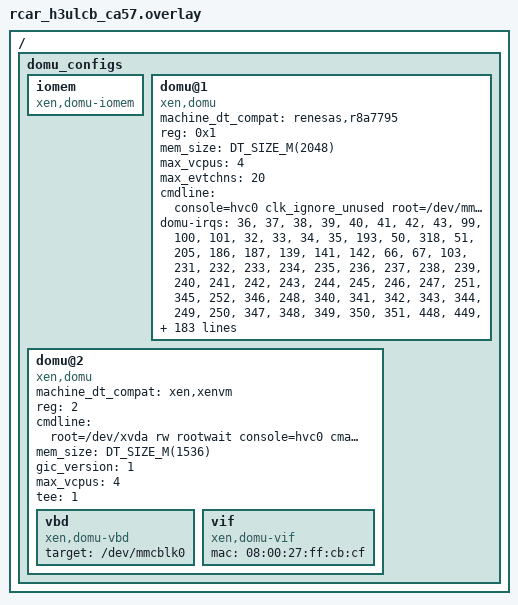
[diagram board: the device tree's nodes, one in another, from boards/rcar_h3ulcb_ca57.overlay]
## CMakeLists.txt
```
# SPDX-License-Identifier: Apache-2.0
# Copyright (c) 2024 EPAM Systems

cmake_minimum_required(VERSION 3.13.1)

find_package(Zephyr REQUIRED HINTS $ENV{ZEPHYR_BASE})

include($ENV{ZEPHYR_BASE}/cmake/app/boilerplate.cmake NO_POLICY_SCOPE)

project(xen-dom0)

include_directories(app PRIVATE ${CMAKE_CURRENT_SOURCE_DIR}/include)

# Add prebuilt to includes so assembler can find this files
include_directories(app PRIVATE ${CMAKE_CURRENT_SOURCE_DIR}/prebuilt)

target_sources(app PRIVATE src/dom0.c src/domain_bins.S)
target_sources_ifdef(CONFIG_DOM_STORAGE_FATFS_ENABLE app PRIVATE src/storage.c)
target_sources_ifdef(CONFIG_DOM_COVERAGE_ENABLE app PRIVATE src/cmd_gcov.c)

if(CONFIG_USE_DEFAULT_DOM_CFG)
  target_sources(app PRIVATE src/domu_cfg.c)
else()
  if(CONFIG_DOM_CFG_BOARD_EXT)
    target_sources(app PRIVATE src/dom_cfg/${BOARD}_${CONFIG_DOM_CFG_BOARD_EXT}.c)
  else()
    target_sources(app PRIVATE src/dom_cfg/${BOARD}.c)
  endif()
endif()

target_sources_ifdef(CONFIG_VCHAN_SHELL_CMDS app PRIVATE src/vchan_cmds.c)
```

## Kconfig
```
# Copyright (c) 2024 EPAM Systems
#
# SPDX-License-Identifier: Apache-2.0

config USE_DEFAULT_DOM_CFG
	bool "Use default guest domain cfg"
	default y
	help
	  Use default guest domain cfg from domu_cfg.c for build.
	  if not selected the guest domain cfg source file will be selected as basing
	  on board/platform:
	    dom_cfg/${BOARD}.c.
	  For example, for RPI 5 the dom_cfg/rpi_5.c will be used.

config DOM_CFG_BOARD_EXT
	string "Use extention string to determine guest domain cfg"
	depends on !USE_DEFAULT_DOM_CFG
	help
	  Use it to add extention string to determine guest domain cfg file to build.
	  The guest domain cfg source file will be selected as following:
	    dom_cfg/${BOARD}_${DOM_CFG_BOARD_EXT}.c
	  This allows to specify number of guest domain configs for the same board.
	  For example:
	    rpi_5_xenvm.c
	    rpi_5_domu.c

config DOM_STORAGE_FATFS_ENABLE
	bool "Enable FATFS disk storage for reading domains kernels/dtb images"
	default n
	select DISK_ACCESS
	select FILE_SYSTEM
	select FAT_FILESYSTEM_ELM
	select XRUN
	help
	  Enables FATFS disk storage and adds possibility to read guest domains
	  kernels/dtb images from storage.

if DOM_STORAGE_FATFS_ENABLE

config DOM_DISK_DRIVE_NAME
	string "Disk drive name for Domain-0"
	default "SD"
	help
	  Used by disk subsys to establish disk access and should be in
	  sync with "disk-name" device tree propery, formerly it was
	  CONFIG_SDMMC_VOLUME_NAME in Zephyr.

config FS_FATFS_MOUNT_MKFS
	default n

config FS_FATFS_WINDOW_ALIGNMENT
	default SDHC_BUFFER_ALIGNMENT

config FS_FATFS_LBA64
	default y

config FS_FATFS_EXFAT
	default y

config DOM_STORAGE_FATFS_DIR
	string "FATFS folder where domains kernels/dtb images"
	default "dom0/"
	help
	  FATFS folder where domains kernels/dtb images are located.
	  It should be ended with "/" symbol.

config DOM_STORAGE_FATFS_LOGICAL_DRIVE_NAME
	string "FATFS logical drive name to be used as mount point"
	default "0" if FS_MULTI_PARTITION
	default DOM_DISK_DRIVE_NAME
	help
	  FATFS logical drive name to be used as mount point.

config DOM_CFG_LINUX_PV_DOMAIN
	bool "Enable PV domain support loaded from FATFS storage"
	help
	  Adds Linux-based domain with enabled pvnet and pvblock devices.
	  It is expected to be placed on the storage device, connected to
	  Dom0.

endif #DOM_STORAGE_FATFS_ENABLE

config DOM_CFG_BUILTIN_IMAGES
	bool "Use built-in guest domains kernel/device-tree images"
	default y
	help
	  Use built-in guest domains kernel/device-tree images.

if DOM_CFG_BUILTIN_IMAGES

config DOM_CFG_DOMU0_IMAGE_BIN_FILE
	string "Location for Domain-U0 kernel binary"
	default "domu0_img.bin"

config DOM_CFG_DOMU0_DTB_BIN_FILE
	string "Location for Domain-U0 device-tree"
	default "domu0.dtb"

config DOM_CFG_DOMU1_ENABLE
	bool "Enable builtin Domain-U1 kernel binary"
	default n

config DOM_CFG_DOMU1_IMAGE_BIN_FILE
	string "Location for Domain-U1 kernel binary"
	depends on DOM_CFG_DOMU1_ENABLE

config DOM_CFG_DOMU1_DTB_BIN_FILE
	string "Location for Domain-U1 device-tree"
	depends on DOM_CFG_DOMU1_ENABLE

endif #DOM_CFG_BUILTIN_IMAGES

config DOM_COVERAGE_ENABLE
	bool "Enable code coverage with GCOV"
	depends on SHELL
	select FORCE_COVERAGE
	select COVERAGE
	help
	  Enable code coverage with GCOV and enable shell command to print GCOV
	  dump "gcov dump" in console.

config VCHAN_SHELL_CMDS
	depends on SHELL
	bool "Enable VCHAN echo server shell commands"
	help
	  Enable set of VCHAN echo server shell commands. All data incoming to
	  channel created by this server will be send back. This is for test
	  purposes. Server introduces 2 commands:
	  vchan start [domid]
	    Start echo server. domid - The peer domain that will be connecting
	    (0 by default)
	  vchan stop
	    Stop server

if VCHAN_SHELL_CMDS

config VCHAN_ECHO_BUFFER_SIZE
	int "Buffer size for echo server"
	default 10

config VCHAN_THREAD_STACK_SIZE
	int "vchan echo server thread size"
	default 2048

endif #VCHAN_SHELL_CMDS

source "Kconfig.zephyr"
```

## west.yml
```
# SPDX-License-Identifier: Apache-2.0
# West YAML manifest for Zephyr as Xen Dom0

manifest:
  self:
    path: zephyr-dom0-xt

  remotes:
    - name: xentroops
      url-base: https://github.com/xen-troops/
    - name: zephyrproject-rtos
      url-base: https://github.com/zephyrproject-rtos/

  projects:
    - name: zephyr
      remote: xentroops
      revision: zephyr-v4.4.0-xt
      west-commands: scripts/west-commands.yml
    - name: zephyr-xenlib
      remote: xentroops
      revision: main
    - name: fatfs
      remote: zephyrproject-rtos
      revision: f4ead3bf4a6dab3a07d7b5f5315795c073db568d
    - name: zephyr-xrun
      remote: xentroops
      revision: main
```

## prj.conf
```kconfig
CONFIG_MP_MAX_NUM_CPUS=1
CONFIG_XEN_STORE_SRV=y
CONFIG_XEN_DOMAIN_MANAGEMENT=y
CONFIG_XEN_SHELL=y
CONFIG_XEN_CONSOLE_SRV=y
CONFIG_HEAP_MEM_POOL_SIZE=2097152
CONFIG_SHELL_STACK_SIZE=4096
CONFIG_XEN_REGIONS=y

CONFIG_LOG=y
CONFIG_LOG_MODE_MINIMAL=y
```

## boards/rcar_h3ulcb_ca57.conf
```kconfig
# Copyright (c) 2024 EPAM Systems
# SPDX-License-Identifier: Apache-2.0

CONFIG_KERNEL_VM_SIZE=0x10000000
CONFIG_CLOCK_CONTROL=n
CONFIG_PINCTRL=n
```

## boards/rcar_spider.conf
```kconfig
# Copyright (c) 2024 EPAM Systems
# SPDX-License-Identifier: Apache-2.0

CONFIG_KERNEL_VM_SIZE=0x10000000
```

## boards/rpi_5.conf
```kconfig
# Copyright (c) 2024 EPAM Systems
# SPDX-License-Identifier: Apache-2.0

CONFIG_XEN_DOM0=y

CONFIG_XSTAT=y
CONFIG_XSTAT_SHELL_CMDS=y

CONFIG_SHELL_STACK_SIZE=4096

CONFIG_MAIN_STACK_SIZE=8192
CONFIG_ISR_STACK_SIZE=8192

CONFIG_XEN_VCH=y
CONFIG_XEN_DOM0LESS_BOOT=y

CONFIG_USE_DEFAULT_DOM_CFG=n
CONFIG_DOM_CFG_BUILTIN_IMAGES=n

CONFIG_DOM_STORAGE_FATFS_ENABLE=y

CONFIG_FILE_SYSTEM_SHELL=y

CONFIG_NOCACHE_MEMORY=y
CONFIG_FS_FATFS_MULTI_PARTITION=y
CONFIG_FS_FATFS_CUSTOM_MOUNT_POINT_COUNT=8
CONFIG_FS_FATFS_CUSTOM_MOUNT_POINTS="RAM,NAND,CF,SD,SD2,USB,USB2,USB3"
CONFIG_DOM_STORAGE_FATFS_LOGICAL_DRIVE_NAME="1"
CONFIG_DOM_STORAGE_FATFS_DIR="dom0/"
CONFIG_XEN_LIBFDT=y

CONFIG_DOM_CFG_LINUX_PV_DOMAIN=y

CONFIG_XRUN_STORAGE_DMA_DEBOUNCE=4

CONFIG_DOMU_MAX=5

CONFIG_XEN_SYSCTL_INTERFACE_VERSION=0x16
CONFIG_XEN_DOMCTL_INTERFACE_VERSION=0x18
CONFIG_XEN_DOMCTL_XENTROOPS_ARCH_VGSX_OSID=y
CONFIG_XEN_DOMCTL_XENTROOPS_ARCH_SCI_TYPE=y

CONFIG_PCIE=n
CONFIG_PCIE_CONTROLLER=n
```

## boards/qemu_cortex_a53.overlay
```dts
/*
 * Copyright (C) 2023 Renesas Electronics Corporation.
 * Copyright (C) 2023 EPAM Systems, Inc.
 *
 * SPDX-License-Identifier: Apache-2.0
 */

#include <mem.h>

/delete-node/ &sram0;

&uart0 {
	/* Xen consoleio will be used */
	status = "disabled";
};

/ {
	/*
	 * This node may differs on different setups, please check
	 * following line in Xen boot log to set it right:
	 * (XEN) Grant table range: 0x00000040200000-0x00000040240000
	 * Also, add extended region 1:
	 * (XEN) Extended region 1: 0x40000000->0x47e00000
	 *
	 * Xen passes actual values for setup in domain device tree, but Zephyr
	 * is not capable to parse and handle it in runtime.
	 */
	hypervisor: hypervisor@40200000 {
		compatible = "xen,xen";
		reg = <0x0 0x40200000 0x0 0x40000 0x0 0x40400000 0x0 0x17C00000>;
		interrupts = <GIC_PPI 0x0 IRQ_TYPE_EDGE IRQ_DEFAULT_PRIORITY>;
		interrupt-parent = <&gic>;
		status = "okay";
	};

	/*
	 * This node may differs on different setups, because Xen picks
	 * region for Domain-0 for every specific configuration. You can
	 * start Xen for your platform and check following log:
	 * (XEN) Allocating 1:1 mappings for dom0:
	 * (XEN) BANK[0] 0x00000058000000-0x00000060000000 (128MB)
	 *
	 * Xen passes actual values for setup in domain device tree, but Zephyr
	 * is not capable to parse and handle it in runtime.
	 */
	soc {
		sram0: memory@58000000 {
			device_type = "mmio-sram";
			reg = <0x00 0x58000000 0x00 DT_SIZE_M(128)>;
		};
	};
};
```

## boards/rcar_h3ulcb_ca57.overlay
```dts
/*
 * Copyright (C) 2024 EPAM Systems, Inc.
 * SPDX-License-Identifier: Apache-2.0
 */
#include <mem.h>

/delete-node/ &sd0;
/delete-node/ &vcc_sd0;
/delete-node/ &vccq_sd0;
/delete-node/ &gpio5;

/ {
	domu_configs {
		#address-cells = <1>;
		#size-cells = <0>;

		/* it is needed only for correct filling structures by macros */
		iomem: iomem {
			compatible = "xen,domu-iomem";
			#iomem-cells = <3>;
		};

		domu@1 {
			/*
			 * Most of the properties of this one and children nodes are default and don't appear
			 * in the resulting dts.
			 *
			 * Refer to 'xen,domu.yaml', 'xen,domu-vbd.yaml' and 'xen,domu-vif.yaml' for details.
			 */
			compatible = "xen,domu";
			machine_dt_compat = "renesas,r8a7795";

			reg = <0x1>;
			mem_size = <DT_SIZE_M(2048)>;
			max_vcpus = <4>;
			max_evtchns = <20>;

			cmdline = "console=hvc0 clk_ignore_unused root=/dev/mmcblk1 rw rootwait pvrsrvkm.DriverMode=0";

			domu-irqs =
				// gpio@e6050000
				<36>,
				// gpio@e6051000
				<37>,
				// gpio@e6052000
				<38>,
				// gpio@e6053000
				<39>,
				// gpio@e6054000
				<40>,
				// gpio@e6055000
				<41>,
				// gpio@e6055400
				<42>,
				// gpio@e6055800
				<43>,
				// thermal@e6198000
				<99>, <100>, <101>,
				// interrupt-controller@e61c0000
				<32>, <33>, <34>, <35>, <193>, <50>,
				// i2c@e6510000
				<318>,
				// i2c@e66d8000
				<51>,
				// i2c@e60b0000
				<205>,
				// serial@e6540000
				<186>,
				// serial@e6550000
				<187>,
				// usb@e6590000
				<139>,
				// dma-controller@e65a0000
				<141>,
				// dma-controller@e65b0000
				<142>,
				// dma-controller@e6460000
				<66>,
				// dma-controller@e6470000
				<67>,
				// crypto@e6601000
				<103>,
				// dma-controller@e6700000
				<231>, <232>, <233>, <234>, <235>, <236>, <237>, <238>, <239>, <240>, <241>, <242>, <243>, <244>, <245>, <246>, <247>,
				// dma-controller@e7300000
				<251>, <345>, <252>, <346>, <248>, <340>, <341>, <342>, <343>, <344>, <249>, <250>, <347>, <348>, <349>, <350>, <351>,
				// dma-controller@e7310000
				<448>, <449>, <450>, <451>, <452>, <453>, <454>, <455>, <456>, <457>, <458>, <459>, <460>, <461>, <462>, <463>, <429>,
				// ethernet@e6800000
				<71>, <72>, <73>, <74>, <75>, <76>, <77>, <78>, <79>, <80>, <81>, <82>, <83>, <84>, <85>, <86>, <87>, <88>, <89>, <90>, <91>, <92>, <93>, <94>, <95>,
				// can@e6c30000
				<218>,
				// can@e6c38000
				<219>,
				// serial@e6e68000
				<185>,
				// video@e6ef0000
				<220>,
				// video@e6ef1000
				<221>,
				// video@e6ef2000
				<222>,
				// video@e6ef3000
				<223>,
				// video@e6ef4000
				<206>,
				// video@e6ef5000
				<207>,
				// src-0
				<384>,
				// src-1
				<385>,
				// src-2
				<386>,
				// src-3
				<387>,
				// src-4
				<388>,
				// src-5
				<389>,
				// src-6
				<390>,
				// src-7
				<391>,
				// src-8
				<392>,
				// src-9
				<393>,
				// ssi-0
				<402>,
				// ssi-1
				<403>,
				// ssi-2
				<404>,
				// ssi-3
				<405>,
				// ssi-4
				<406>,
				// ssi-5
				<407>,
				// ssi-6
				<408>,
				// ssi-7
				<409>,
				// ssi-8
				<410>,
				// ssi-9
				<411>,
				// dma-controller@ec700000
				<352>, <353>, <354>, <355>, <356>, <357>, <358>, <359>, <360>, <361>, <362>, <363>, <364>, <365>, <366>, <367>, <382>,
				// dma-controller@ec720000
				<383>, <368>, <369>, <370>, <371>, <372>, <373>, <374>, <375>, <376>, <377>, <378>, <379>, <380>, <381>, <414>, <415>,
				// usb@ee000000
				<134>,
				// usb@ee080000
				<140>,
				// usb@ee0a0000
				<144>,
				// mmc@ee100000
				<197>,
				// mmc@ee140000
				<199>,
				// mmc@ee160000
				<200>,
				// gsx@fd000000
				<151>,
				// pcie@fe000000
				<148>, <149>, <150>,
				// pcie@ee800000
				<180>, <181>, <182>,
				// imr-lx4@fe860000
				<224>,
				// imr-lx4@fe870000
				<225>,
				// imr-lx4@fe880000
				<226>,
				// imr-lx4@fe890000
				<227>,
				// vcp4@fe8d0000
				<412>, <413>, <255>,
				// vcp4@fe910000
				<292>, <293>,
				// vcp4@fe900000
				<272>, <273>,
				// fdpm@fe940000
				<294>,
				// fdpm@fe944000
				<295>,
				// vspm@fe960000
				<298>,
				// vspm@fe920000
				<497>,
				// vsp@fea20000
				<498>,
				// vsp@fea28000
				<499>,
				// vsp@fea30000
				<500>,
				// vspm@fe9a0000
				<476>,
				// vspm@fe9b0000
				<477>,
				// csi2@fea80000
				<216>,
				// csi2@feaa0000
				<278>,
				// hdmi@fead0000
				<421>,
				// display@feb00000
				<288>, <300>, <301>, <302>,
				// impdes0
				<471>,
				// imprtt
				<425>,
				// dma-controller@ffc10000
				<480>, <481>, <482>, <483>, <484>, <485>, <486>, <487>, <488>,
				// dma-controller@ffc20000
				<501>, <489>, <490>, <491>, <492>, <493>, <494>, <495>, <496>;

			dt-passthrough =
				"/audio_clk_a",
				"/audio_clk_b",
				"/audio_clk_c",
				"/can",
				"/extal",
				"/extalr",
				"/gsx_opp_table0",
				"/gsx_opp_table1",
				"/gsx_opp_table2",
				"/gsx_opp_table3",
				"/gsx_opp_table4",
				"/gsx_opp_table5",
				"/gsx_opp_table6",
				"/gsx_opp_table7",
				"/pcie_bus",
				"/scif",
				"/soc",
				"/usb3s0",
				"/usb_extal",
				"/audio-clkout",
				"/avb-mch",
				"/hdmi0-out",
				"/keyboard",
				"/leds",
				"/regulator0",
				"/regulator1",
				"/regulator-vcc-sdhi0",
				"/regulator-vccq-sdhi0",
				"/x12",
				"/x23-clock",
				"/vspm_if",
				"/versaclk-3",
				"/versaclk-4",
				"/clksndsel",
				"/regulator-snd_3p3v",
				"/regulator-snd_vcc5v",
				"/regulator-wlan_en",
				"/regulator@9",
				"/regulator@11",
				"/regulator@12",
				"/regulator@13",
				"/regulator@14",
				"/regulator@15",
				"/regulator@16",
				"/regulator@17",
				"/kim",
				"/sound@0",
				"/sound@1",
				"/sound@2",
				"/sound@3",
				"/lvds",
				"/hdmi-out",
				"/si468x@0",
				"/wl18xx_pcm@0",
				"/camera_clk",
				"/ov5647_camera_clk",
				"/reserved-memory",
				"/mmngr",
				"/mmngrbuf",
				"/__symbols__";

			dtdevs =
				"/soc/dma-controller@e65a0000",
				"/soc/dma-controller@e65b0000",
				"/soc/dma-controller@e6460000",
				"/soc/dma-controller@e6470000",
				"/soc/dma-controller@e6700000",
				"/soc/dma-controller@e7300000",
				"/soc/dma-controller@e7310000",
				"/soc/ethernet@e6800000",
				"/soc/video@e6ef0000",
				"/soc/video@e6ef1000",
				"/soc/video@e6ef2000",
				"/soc/video@e6ef3000",
				"/soc/video@e6ef4000",
				"/soc/video@e6ef5000",
				"/soc/dma-controller@ec700000",
				"/soc/dma-controller@ec720000",
				"/soc/usb@ee000000",
				"/soc/usb@ee080000",
				"/soc/usb@ee0a0000",
				"/soc/usb@ee080100",
				"/soc/usb@ee0a0100",
				"/soc/mmc@ee100000",
				"/soc/mmc@ee140000",
				"/soc/mmc@ee160000",
				"/soc/pcie@fe000000",
				"/soc/pcie@ee800000",
				"/soc/imr-lx4@fe860000",
				"/soc/imr-lx4@fe870000",
				"/soc/imr-lx4@fe880000",
				"/soc/imr-lx4@fe890000",
				"/soc/fdpm@fe940000",
				"/soc/fdpm@fe944000",
				"/soc/fcp@fea27000",
				"/soc/fcp@fea2f000",
				"/soc/fcp@fea37000",
				"/soc/vspm@fe960000",
				"/soc/vspm@fe920000",
				"/soc/vspm@fe9a0000",
				"/soc/vspm@fe9b0000",
				"/soc/hdmi@fead0000",
				"/soc/impdm0",
				"/soc/gsx_pv0_domd",
				"/soc/gsx_pv1_domd",
				"/soc/gsx_pv2_domd",
				"/soc/gsx_pv3_domd",
				"/soc/fcpcs_vc0",
				"/soc/fcpcs_vc1",
				"/soc/dma-controller@ffc10000",
				"/soc/dma-controller@ffc20000";

			iomems =
				<&iomem 0x47fd7 0x1 0xe0000>,
				// 1:1 mapped lossy_decompress region
				<&iomem 0x54000 0x3000 0x0>,
				// mfis@e6260000
				<&iomem 0xe6260 0x1 0x0>,
				// watchdog@e6020000
				<&iomem 0xe6020 0x1 0x0>,
				// gpio@e6050000
				<&iomem 0xe6050 0x1 0x0>,
				// gpio@e6051000
				<&iomem 0xe6051 0x1 0x0>,
				// gpio@e6052000
				<&iomem 0xe6052 0x1 0x0>,
				// gpio@e6053000
				<&iomem 0xe6053 0x1 0x0>,
				// gpio@e6054000
				<&iomem 0xe6054 0x1 0x0>,
				// gpio@e6055000
				// gpio@e6055400
				// gpio@e6055800
				<&iomem 0xe6055 0x1 0x0>,
				// pinctrl@e6060000
				<&iomem 0xe6060 0x1 0x0>,
				// avs@e60a013c
				<&iomem 0xe60a0 0x1 0x0>,
				// clock-controller@e6150000
				// imprtt
				<&iomem 0xe6150 0x1 0x0>,
				// reset-controller@e6160000
				<&iomem 0xe6160 0x1 0x0>,
				// system-controller@e6180000
				<&iomem 0xe6180 0x1 0x0>,
				// thermal@e6198000
				<&iomem 0xe6198 0x1 0x0>,
				// thermal@e6198000
				<&iomem 0xe61a0 0x1 0x0>,
				// thermal@e6198000
				<&iomem 0xe61a8 0x1 0x0>,
				// interrupt-controller@e61c0000
				<&iomem 0xe61c0 0x1 0x0>,
				// i2c@e6510000
				<&iomem 0xe6510 0x1 0x0>,
				// i2c@e66d8000
				<&iomem 0xe66d8 0x1 0x0>,
				// i2c@e60b0000
				<&iomem 0xe60b0 0x1 0x0>,
				// serial@e6540000
				<&iomem 0xe6540 0x1 0x0>,
				// serial@e6550000
				<&iomem 0xe6550 0x1 0x0>,
				// usb@e6590000
				<&iomem 0xe6590 0x1 0x0>,
				// dma-controller@e65a0000
				<&iomem 0xe65a0 0x1 0x0>,
				// dma-controller@e65b0000
				<&iomem 0xe65b0 0x1 0x0>,
				// dma-controller@e6460000
				<&iomem 0xe6460 0x1 0x0>,
				// dma-controller@e6470000
				<&iomem 0xe6470 0x1 0x0>,
				// crypto@e6601000
				<&iomem 0xe6601 0x1 0x0>,
				// dma-controller@e6700000
				<&iomem 0xe6700 0x10 0x0>,
				// dma-controller@e7300000
				<&iomem 0xe7300 0x10 0x0>,
				// dma-controller@e7310000
				<&iomem 0xe7310 0x10 0x0>,
				// qos@e67e0000
				<&iomem 0xe67e0 0x11 0x0>,
				// ethernet@e6800000
				<&iomem 0xe6800 0x1 0x0>,
				// ethernet@e6800000
				<&iomem 0xe6a00 0x10 0x0>,
				// can@e6c30000
				<&iomem 0xe6c30 0x1 0x0>,
				// can@e6c38000
				<&iomem 0xe6c38 0x1 0x0>,
				// serial@e6e68000
				<&iomem 0xe6e68 0x1 0x0>,
				// video@e6ef0000
				<&iomem 0xe6ef0 0x1 0x0>,
				// video@e6ef1000
				<&iomem 0xe6ef1 0x1 0x0>,
				// video@e6ef2000
				<&iomem 0xe6ef2 0x1 0x0>,
				// video@e6ef3000
				<&iomem 0xe6ef3 0x1 0x0>,
				// video@e6ef4000
				<&iomem 0xe6ef4 0x1 0x0>,
				// video@e6ef5000
				<&iomem 0xe6ef5 0x1 0x0>,
				// sound@ec500000
				<&iomem 0xec500 0x1 0x0>,
				// sound@ec500000
				// avb-mch
				<&iomem 0xec5a0 0x1 0x0>,
				// sound@ec500000
				<&iomem 0xec540 0x1 0x0>,
				// sound@ec500000
				<&iomem 0xec541 0x1 0x0>,
				// sound@ec500000
				<&iomem 0xec760 0x1 0x0>,
				// sound@ec500000
				<&iomem 0xec000 0x1 0x0>,
				// sound@ec500000
				<&iomem 0xec008 0x1 0x0>,
				// sound@ec500000
				<&iomem 0xec100 0x100 0x0>,
				// dma-controller@ec700000
				<&iomem 0xec700 0x10 0x0>,
				// dma-controller@ec720000
				<&iomem 0xec720 0x10 0x0>,
				// usb@ee000000
				<&iomem 0xee000 0x1 0x0>,
				// usb@ee080000
				// usb@ee080100
				// usb-phy@ee080200
				<&iomem 0xee080 0x1 0x0>,
				// usb@ee0a0000
				// usb@ee0a0100
				// usb-phy@ee0a0200
				<&iomem 0xee0a0 0x1 0x0>,
				// mmc@ee100000
				<&iomem 0xee100 0x2 0x0>,
				// mmc@ee140000
				<&iomem 0xee140 0x2 0x0>,
				// mmc@ee160000
				<&iomem 0xee160 0x2 0x0>,
				// gsx@fd000000
				<&iomem 0xfd000 0x40 0x0>,
				// pcie@fe000000
				<&iomem 0xfe000 0x80 0x0>,
				// pcie@ee800000
				<&iomem 0xee800 0x80 0x0>,
				// imr-lx4@fe860000
				// imrlx4_imr0
				<&iomem 0xfe860 0x2 0x0>,
				// imr-lx4@fe870000
				// imrlx4_imr1
				<&iomem 0xfe870 0x2 0x0>,
				// imr-lx4@fe880000
				// imrlx4_imr2
				<&iomem 0xfe880 0x2 0x0>,
				// imr-lx4@fe890000
				// imrlx4_imr3
				<&iomem 0xfe890 0x2 0x0>,
				// vcp4@fe90f000
				<&iomem 0xfe90f 0x1 0x0>,
				// vcp4@fe8d0000
				// vcp4@fe8d0000
				<&iomem 0xfe8d0 0x1 0x0>,
				// vcp4@fe910000
				// vcp4@fe910000
				<&iomem 0xfe910 0x1 0x0>,
				// vcp4@fe900000
				// vcp4@fe900000
				<&iomem 0xfe900 0x1 0x0>,
				// fdpm@fe940000
				<&iomem 0xfe940 0x3 0x0>,
				// fdpm@fe940000
				<&iomem 0xfe950 0x1 0x0>,
				// fdpm@fe944000
				<&iomem 0xfe944 0x3 0x0>,
				// fdpm@fe944000
				<&iomem 0xfe951 0x1 0x0>,
				// fcp@fea27000
				<&iomem 0xfea27 0x1 0x0>,
				// fcp@fea2f000
				<&iomem 0xfea2f 0x1 0x0>,
				// fcp@fea37000
				<&iomem 0xfea37 0x1 0x0>,
				// vsp@fe960000
				// vspm@fe960000
				<&iomem 0xfe960 0x8 0x0>,
				// vspm@fe960000
				<&iomem 0xfe96f 0x1 0x0>,
				// vsp@fe920000
				// vspm@fe920000
				<&iomem 0xfe920 0x8 0x0>,
				// vspm@fe920000
				<&iomem 0xfe92f 0x1 0x0>,
				// vsp@fea20000
				<&iomem 0xfea20 0x5 0x0>,
				// vsp@fea28000
				<&iomem 0xfea28 0x5 0x0>,
				// vsp@fea30000
				<&iomem 0xfea30 0x5 0x0>,
				// vsp@fe9a0000
				// vspm@fe9a0000
				<&iomem 0xfe9a0 0x8 0x0>,
				// vspm@fe9a0000
				<&iomem 0xfe9af 0x1 0x0>,
				// vsp@fe9b0000
				// vspm@fe9b0000
				<&iomem 0xfe9b0 0x8 0x0>,
				// vspm@fe9b0000
				<&iomem 0xfe9bf 0x1 0x0>,
				// csi2@fea80000
				<&iomem 0xfea80 0x10 0x0>,
				// csi2@feaa0000
				<&iomem 0xfeaa0 0x10 0x0>,
				// hdmi@fead0000
				<&iomem 0xfead0 0x10 0x0>,
				// display@feb00000
				<&iomem 0xfeb00 0x80 0x0>,
				// lvds@feb90000
				<&iomem 0xfeb90 0x1 0x0>,
				// chipid@fff00044
				<&iomem 0xfff00 0x1 0x0>,
				// impdes0
				<&iomem 0xffa00 0x4 0x0>,
				// imp0
				<&iomem 0xff900 0x20 0x0>,
				// imp1
				<&iomem 0xff920 0x20 0x0>,
				// imp2
				<&iomem 0xff940 0x20 0x0>,
				// imp3
				<&iomem 0xff960 0x20 0x0>,
				// impsc0
				<&iomem 0xff980 0x10 0x0>,
				// impsc1
				<&iomem 0xff990 0x10 0x0>,
				// impsl0
				<&iomem 0xff9c0 0x10 0x0>,
				// impdm0
				<&iomem 0xffa10 0x4 0x0>,
				// impc0
				<&iomem 0xffa40 0x20 0x0>,
				// imprtt
				<&iomem 0xff8d0 0x1 0x0>,
				// dma-controller@ffc10000
				<&iomem 0xffc10 0x10 0x0>,
				// dma-controller@ffc20000
				<&iomem 0xffc20 0x10 0x0>,
				// cmm@fea40000
				<&iomem 0xfea40 0x1 0x0>,
				// cmm@fea50000
				<&iomem 0xfea50 0x1 0x0>,
				// cmm@fea60000
				<&iomem 0xfea60 0x1 0x0>,
				// cmm@fea70000
				<&iomem 0xfea70 0x1 0x0>;
		};

		domu@2 {
			compatible = "xen,domu";
			machine_dt_compat = "xen,xenvm";
			reg = <2>;

			cmdline = "root=/dev/xvda rw rootwait console=hvc0 cma=256M pvrsrvkm.DriverMode=1";

			mem_size = <DT_SIZE_M(1536)>;
			gic_version = <1>;
			max_vcpus = <4>;
			tee = <1>;

			vbd {
				compatible = "xen,domu-vbd";
				target = "/dev/mmcblk0";
			};

			vif {
				compatible = "xen,domu-vif";
				mac = "08:00:27:ff:cb:cf";
			};

			status = "okay";
		};
	};
};
```

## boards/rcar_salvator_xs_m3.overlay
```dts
/*
 * Copyright (C) 2023 Renesas Electronics Corporation.
 * Copyright (C) 2023 EPAM Systems, Inc.
 *
 * SPDX-License-Identifier: Apache-2.0
 */

#include <mem.h>

/delete-node/ &ram;

/ {
	/*
	 * This node may differs on different setups, please check
	 * following line in Xen boot log to set it right:
	 * (XEN) Grant table range: 0x00000088080000-0x000000880c0000
	 * Also, add extended region 2:
	 * (XEN) [    0.928173] d0: extended region 2: 0x40000000->0x47e00000
	 *
	 * Xen passes actual values for setup in domain device tree, but Zephyr
	 * is not capable to parse and handle it in runtime.
	 */
	hypervisor: hypervisor@88080000 {
		compatible = "xen,xen";
		reg = <0x0 0x88080000 0x0 0x40000 0x0 0x40000000 0x0 0x7e00000>;
		interrupts = <GIC_PPI 0x0 IRQ_TYPE_EDGE IRQ_DEFAULT_PRIORITY>;
		interrupt-parent = <&gic>;
		status = "okay";
	};

	/*
	 * This node may differs on different setups, because Xen picks
	 * region for Domain-0 for every specific configuration. You can
	 * start Xen for your platform and check following log:
	 * (XEN) Allocating 1:1 mappings for dom0:
	 * (XEN) BANK[0] 0x00000060000000-0x00000070000000 (256MB)
	 *
	 * Xen passes actual values for setup in domain device tree, but Zephyr
	 * is not capable to parse and handle it in runtime.
	 */
	ram: memory@60000000 {
		device_type = "mmio-sram";
		reg = <0x00 0x60000000 0x00 DT_SIZE_M(256)>;
	};
};
```

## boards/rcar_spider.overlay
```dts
/*
 * Copyright (C) 2024 EPAM Systems, Inc.
 * SPDX-License-Identifier: Apache-2.0
 */
#include <mem.h>

/ {
	domu_configs {
		#address-cells = <1>;
		#size-cells = <0>;

		/* it is needed only for correct filling structures by macros */
		iomem: iomem {
			compatible = "xen,domu-iomem";
			#iomem-cells = <3>;
		};

		domu@1 {
			/*
			 * Most of the properties of this one and children nodes are default and don't appear
			 * in the resulting dts.
			 *
			 * Refer to 'xen,domu.yaml', 'xen,domu-vbd.yaml' and 'xen,domu-vif.yaml' for details.
			 */
			compatible = "xen,domu";
			machine_dt_compat = "renesas,r8a779f0";

			reg = <0x1>;
			mem_size = <DT_SIZE_M(1024)>;
			cmdline = "console=hvc0 clk_ignore_unused root=/dev/nfs rw rootwait nfsroot=192.168.1.100:/srv/domd,vers=3 ip=dhcp pci=pcie_bus_perf";

			gic_version = <2>;
			max_vcpus = <4>;
			tee = <1>;

			domu-irqs =
				// gpio@e6050180
				<854>,
				// gpio@e6050980
				<858>,
				// gpio@e6051180
				<948>,
				// gpio@e6051980
				<952>,
				// i2c@e6500000
				<270>,
				// i2c@e66d8000
				<274>,
				// serial@e6550000
				<278>,
				// serial@e6e60000
				<281>,
				// serial@e6c50000 - used by Xen
				//    <284>,
				// dma-controller@e7350000
				<133>, <134>, <135>, <136>, <137>, <138>, <139>, <140>, <141>, <142>, <143>, <144>, <145>, <146>, <147>, <148>, <149>,
				// dma-controller@e7351000
				<151>, <158>, <157>, <152>, <179>, <180>, <181>, <182>, <183>, <184>, <185>, <186>, <155>, <156>, <154>, <153>, <159>,
				// mmc@ee140000
				<268>,
				// dma-controller@ffd60000
				<64>, <65>, <66>, <67>, <68>, <69>, <70>, <71>, <72>, <73>, <74>, <75>, <76>, <77>, <61>, <62>, <63>,
				// dma-controller@ffd61000
				<79>, <80>, <81>, <82>, <83>, <84>, <85>, <86>, <87>, <88>, <89>, <90>, <91>, <92>, <93>, <94>, <95>,
				// dma-controller@ffd62000
				<97>, <98>, <99>, <100>, <101>, <102>, <103>, <104>, <105>, <106>, <107>, <108>, <109>, <110>, <111>, <112>, <113>,
				// dma-controller@ffd63000
				<128>, <129>, <130>, <131>, <115>, <116>, <117>, <118>, <119>, <120>, <121>, <122>, <123>, <124>, <125>, <126>, <127>,
				// pcie@e65d0000
				<448>, <449>, <450>, <451>, <452>, <453>, <454>,
				// iccom00
				<352>,
				// iccom01
				<354>,
				// iccom02
				<356>,
				// iccom03
				<358>,
				// iccom04
				<360>,
				// iccom05
				<362>,
				// iccom06
				<364>,
				// iccom07
				<366>,
				// iccom016
				<386>,
				// iccom017
				<388>,
				// iccom018
				<390>,
				// iccom019
				<392>,
				// iccom020
				<394>,
				// iccom021
				<396>,
				// iccom022
				<398>,
				// iccom023
				<400>,
				// ethernet@e68c0000
				<312>, <313>, <314>, <315>, <316>, <317>, <318>, <319>, <320>, <321>,
				<322>, <323>, <324>, <325>, <326>, <327>, <328>, <329>, <330>, <331>,
				// scsi@e6860000 (UFS)
				<267>;

			dt-passthrough =
				"/extal",
				"/extalr",
				"/msiof-ref-clock",
				"/ufs30_refclk_v",
				"/pcie_bus",
				"/scif",
				"/soc",
				"/regulator-1p8v",
				"/regulator-3p3v",
				"/regulator-vcc-sdhi",
				"/reserved-memory";

			dtdevs =
				"/soc/dma-controller@e7350000",
				"/soc/dma-controller@e7351000",
				"/soc/mmc@ee140000",
				"/soc/ethernet@e68c0000",
				"/soc/pcie@e65d0000",
				"/soc/scsi@e6860000";

			iomems =
				// iccom shared memory (CTA) - CR52
				<&iomem 0x47fc7 0x2 0x37fc7>,

				// watchdog@e6020000
				<&iomem 0xe6020 0x1 0x0>,
				// pin-controller@e6050000
				// pin-controller@e6050000
				// gpio@e6050180
				// gpio@e6050980
				<&iomem 0xe6050 0x1 0x0>,
				// pin-controller@e6050000
				// pin-controller@e6050000
				// gpio@e6051180
				// gpio@e6051980
				<&iomem 0xe6051 0x1 0x0>,
				// pin-controller@e6050000
				// pin-controller@e6050000
				<&iomem 0xdfd90 0x1 0x0>,
				// pin-controller@e6050000
				// pin-controller@e6050000
				<&iomem 0xdfd91 0x1 0x0>,
				// clock-controller@e6150000
				<&iomem 0xe6150 0x4 0x0>,
				// reset-controller@e6160000
				<&iomem 0xe6160 0x4 0x0>,
				// system-controller@e6180000
				<&iomem 0xe6180 0x4 0x0>,
				// i2c@e6500000
				<&iomem 0xe6500 0x1 0x0>,
				// i2c@e66d8000
				<&iomem 0xe66d8 0x1 0x0>,
				// ethernet@e68c0000
				<&iomem 0xe68c0 0x20 0x0>,
				// ethernet@e68c0000
				<&iomem 0xe6444 0x3 0x0>,
				// serial@e6550000
				<&iomem 0xe6550 0x1 0x0>,
				// serial@e6e60000
				<&iomem 0xe6e60 0x1 0x0>,
				// dma-controller@e7350000
				<&iomem 0xe7350 0x1 0x0>,
				// dma-controller@e7350000
				<&iomem 0xe7300 0x10 0x0>,
				// dma-controller@e7351000
				<&iomem 0xe7351 0x1 0x0>,
				// dma-controller@e7351000
				<&iomem 0xe7310 0x10 0x0>,
				// mmc@ee140000
				<&iomem 0xee140 0x2 0x0>,
				// chipid@fff00044
				<&iomem 0xfff00 0x1 0x0>,
				// dma-controller@ffd60000
				<&iomem 0xffd60 0x1 0x0>,
				// dma-controller@ffd60000
				<&iomem 0xffc10 0x10 0x0>,
				// dma-controller@ffd61000
				<&iomem 0xffd61 0x1 0x0>,
				// dma-controller@ffd61000
				<&iomem 0xffc20 0x10 0x0>,
				// dma-controller@ffd62000
				<&iomem 0xffd62 0x1 0x0>,
				// dma-controller@ffd62000
				<&iomem 0xffd70 0x10 0x0>,
				// dma-controller@ffd63000
				<&iomem 0xffd63 0x1 0x0>,
				// dma-controller@ffd63000
				<&iomem 0xffd80 0x10 0x0>,
				// pcie@e65d0000
				<&iomem 0xe65d3 0x2 0x0>,
				// pcie@e65d0000
				<&iomem 0xe65d5 0x2 0x0>,
				// pcie@e65d0000
				<&iomem 0xe65d6 0x1 0x0>,
				// pcie@e65d0000
				<&iomem 0xe65d7 0x1 0x0>,
				// thermal@e6198000
				<&iomem 0xe6198 0x1 0x0>,
				<&iomem 0xe61a0 0x1 0x0>,
				<&iomem 0xe61a8 0x1 0x0>,
				<&iomem 0xe61b0 0x1 0x0>,
				// iccom_reg_00 - mfis@e6260000
				// iccom00-iccom015, iccom100-iccom115
				<&iomem 0xe6260 0x10 0x0>,
				// scsi@e6860000 (UFS)
				<&iomem 0xe6860 0x1 0x0>,
				<&iomem 0xe6078 0x1 0x0>;
		};

		domu@2 {
			compatible = "xen,domu";
			machine_dt_compat = "xen,xenvm";
			reg = <2>;

			cmdline = "console=hvc0 root=/dev/nfs nfsroot=192.168.1.100:/srv/domu,vers=3 ip=dhcp pci=pcie_bus_perf";

			mem_size = <DT_SIZE_M(512)>;
			max_vcpus = <2>;
			gic_version = <2>;

			vbd {
				compatible = "xen,domu-vbd";
				target = "/dev/sda";
			};

			vif {
				compatible = "xen,domu-vif";
				mac = "08:00:27:ff:cb:ce";
			};

			status = "okay";
		};
	};
};
```

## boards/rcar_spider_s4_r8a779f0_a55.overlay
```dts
/*
 * Copyright (C) 2023 Renesas Electronics Corporation.
 * Copyright (C) 2023 EPAM Systems, Inc.
 *
 * SPDX-License-Identifier: Apache-2.0
 */

#include <mem.h>

/delete-node/ &ram;

/ {
	/*
	 * This node may differs on different setups, please check
	 * following line in Xen boot log to set it right:
	 * (XEN) Grant table range: 0x00000078080000-0x000000780c0000
	 * Also, add extended region 1:
	 * (XEN) Extended region 1: 0x40000000->0x47e00000
	 *
	 * Xen passes actual values for setup in domain device tree, but Zephyr
	 * is not capable to parse and handle it in runtime.
	 */

	hypervisor: hypervisor@78080000 {
		compatible = "xen,xen";
		reg = <0x0 0x78080000 0x0 0x40000 0x0 0x40000000 0x0 0x7e00000>;
		interrupts = <GIC_PPI 0x0 IRQ_TYPE_EDGE IRQ_DEFAULT_PRIORITY>;
		interrupt-parent = <&gic>;
		status = "okay";
	};

	/*
	 * This node may differs on different setups, because Xen picks
	 * region for Domain-0 for every specific configuration. You can
	 * start Xen for your platform and check following log:
	 * (XEN) Allocating 1:1 mappings for dom0:
	 * (XEN) BANK[0] 0x00000080000000-0x00000090000000 (256MB)
	 *
	 * Xen passes actual values for setup in domain device tree, but Zephyr
	 * is not capable to parse and handle it in runtime.
	 */
	ram: memory@80000000 {
		device_type = "mmio-sram";
		reg = <0x00 0x80000000 0x00 DT_SIZE_M(256)>;
	};
};
```

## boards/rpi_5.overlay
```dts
/*
 * Copyright (C) 2024 EPAM Systems.
 *
 * SPDX-License-Identifier: Apache-2.0
 */

 /delete-node/ &sram0;
 /delete-node/ &pcie2;
 /delete-node/ &pcie1;
 /delete-node/ &rng;

#include <mem.h>

/ {
	#address-cells = <2>;
	#size-cells = <1>;

	chosen {
		zephyr,console = &xen_consoleio_hvc;
		zephyr,shell-uart = &xen_consoleio_hvc;
		/delete-property/ zephyr,pcie-controller;
		/delete-property/ zephyr,entropy;
	};

	psci {
		method = "hvc";
	};

	xen_consoleio_hvc: hvc {
		compatible = "xen,hvc-consoleio";
		status = "okay";
	};

	/*
	 * This node may differs on different setups, please check
	 * following line in Xen boot log to set it right:
	 * (XEN) Grant table range: 0x00000002800000-0x00000002840000
	 * Also, add extended region 1:
	 * (XEN) d0: extended region 1: 0x40000000->0x5fe00000
	 *
	 * Xen passes actual values for setup in domain device tree, but Zephyr
	 * is not capable to parse and handle it in runtime.
	 */
	hypervisor: hypervisor@2000000 {
		compatible = "xen,xen";
		reg = <0x00 0x2000000 0x40000>, <0x00 0x2200000 0x5400000>;
		interrupts = <GIC_PPI 0x0 IRQ_TYPE_EDGE IRQ_DEFAULT_PRIORITY>;
		interrupt-parent = <&gic>;
		status = "okay";
	};

	/*
	 * This node may differs on different setups, because Xen picks
	 * region for Domain-0 for every specific configuration. You can
	 * start Xen for your platform and check following log:
	 * (XEN) Allocating 1:1 mappings totalling 512MB for dom0:
	 * (XEN) BANK[0] 0x00000060000000-0x00000080000000 (512MB)
	 * (XEN) Loading zImage from 0000000000080000 to 0000000060000000-0000000060038004
	 *
	 * Xen passes actual values for setup in domain device tree, but Zephyr
	 * is not capable to parse and handle it in runtime.
	 */
	sram0: memory@10000000 {
		compatible = "mmio-sram";
		reg = <0x00 0x10000000 DT_SIZE_M(128)>;
	};
};

&uart10 {
	status = "disabled";
};
```

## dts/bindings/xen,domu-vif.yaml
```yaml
# Copyright (c) 2024 EPAM Systems
# SPDX-License-Identifier: Apache-2.0

description: Xen DomU configuration for virtual network interface
compatible: "xen,domu-vif"

include: base.yaml

properties:
  backend_domain_id:
    type: int
    default: 1
    description: |
      Designates a backend domain ID for the device.
      Specifies the backend domain ID which this device should attach to.

  script:
    type: string
    default: "/etc/xen/scripts/vif-bridge"
    description: |
      Specifies the hotplug script to run to configure this device (e.g. to add it to
      the relevant bridge).

  mac:
    type: string
    required: true # TODO: Remove when MAC generation is introduced in xen-dom-mgmt
    description: |
      If specified then this option specifies the MAC address inside the guest of this VIF device.
      The value is a 48-bit number represented as six groups of two hexadecimal digits, separated
      by colons.

      The default if this property is not specified is to be automatically generate a MAC address.

  bridge:
    type: string
    default: "xenbr0"
    description: |
      Specifies the name of the network bridge which this VIF should be added to. The bridge must
      be configured using your distribution's network configuration tools.

  vif_type:
    type: string
    default: "vif"
    description: |
      This keyword is valid for HVM guests only.
      Specifies the type of device to valid values are:

        "ioemu" -- this device will be provided as an emulate device to the guest and
                   also as a paravirtualised device which the guest may choose to use
                   instead if it has suitable drivers available.

        "vif"   -- this device will be provided as a paravirtualised device only.

  ip:
    type: string
    description: |
      Specifies the IP address for the device, the default is not to specify an IP address.

      What, if any, effect this has depends on the hotplug script which is configured. A typically
      behaviour (exhibited by the example hotplug scripts) if set might be to configure firewall
      rules to allow only the specified IP address to be used by the guest (blocking all others).
```

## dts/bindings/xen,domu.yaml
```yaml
# Copyright (c) 2024 EPAM Systems
# SPDX-License-Identifier: Apache-2.0

description: Xen DomU configuration
compatible: "xen,domu"

include: base.yaml

properties:
  reg:
    required: true
    description: Domain ID

  machine_dt_compat:
    type: string
    required: true

  mem_size:
    type: int
    default: 0x8000000 # by default 128M
    description: Size of the RAM given to domain

  max_evtchns:
    type: int
    default: 10

  max_vcpus:
    type: int
    default: 1

  gnt_frames:
    type: int
    default: 32

  max_maptrack_frames:
    type: int
    default: 1

  gic_version:
    type: int
    enum:
      - 0 # GIC Native
      - 1 # GICv2
      - 2 # GICv3
    default: 1

  cmdline:
    type: string
    default: "root=/dev/xvda rw rootwait console=hvc0"

  tee:
    type: int
    enum:
      - 0 # None
      - 1 # OP-TEE
    default: 0

  domu-irqs:
    type: array
    description: |
      Allow a guest to access specific physical IRQs.
      It is recommended to only use this option for trusted VMs under administrator's control.

  iomems:
    type: phandle-array
    description: |
      Allow auto-translated domains to access specific hardware I/O memory pages.
      This array has the next format: <IOMEM_START, NUM_PAGES, GFN>.

      IOMEM_START is a physical page number. NUM_PAGES is the number of pages, beginning
      with START_PAGE, to allow access to. GFN specifies the guest frame number where the
      mapping will start in the guest's address space. If GFN is not specified, the mapping
      will be performed using IOMEM_START as a start in the guest's address space, therefore
      performing a 1:1 mapping by default. All of these values must be given in hexadecimal
      format.

      Note that the IOMMU won't be updated with the mappings specified with this option.
      This option therefore should not be used to pass through any IOMMU-protected devices.

      It is recommended to only use this option for trusted VMs under administrator's control.

  dtdevs:
    type: string-array
    description: |
      Specifies the host device tree nodes to pass through to this guest.
      Each dtdev path is an absolute path in the device tree.

  dt-passthrough:
    type: string-array
```

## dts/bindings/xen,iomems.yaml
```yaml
# Copyright (c) 2024 EPAM Systems
# SPDX-License-Identifier: Apache-2.0

description: Xen DomU IO memory node
compatible: "xen,domu-iomem"

include: base.yaml

properties:
  "#iomem-cells":
    type: int
    required: true
    const: 3

iomem-cells:
  - first_mfn
  - nr_mfns
  - first_gfn
```

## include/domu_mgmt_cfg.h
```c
/*
 * Copyright (c) 2024 EPAM Systems
 * SPDX-License-Identifier: Apache-2.0
 */
#ifndef __DOMU_MGMT_CFG_H__
#define __DOMU_MGMT_CFG_H__

#include <stdint.h>

extern char __img_d_start[];
extern char __img_d_end[];

extern char __dtb_d_start[];
extern char __dtb_d_end[];

extern char __img_u_start[];
extern char __img_u_end[];

extern char __dtb_u_start[];
extern char __dtb_u_end[];

int find_cfg_and_create_domu(uint32_t domid);
void create_and_unpause_domus(void);

#endif /* __DOMU_MGMT_CFG_H__ */
```

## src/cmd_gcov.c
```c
/*
 * Copyright (c) 2024 EPAM Systems
 *
 * SPDX-License-Identifier: Apache-2.0
 */

#include <zephyr/kernel.h>
#include <zephyr/shell/shell.h>
#include <zephyr/debug/gcov.h>

static int gcov_dump(const struct shell *shell, size_t argc, char **argv)
{
	gcov_coverage_dump();

	return 0;
}

SHELL_STATIC_SUBCMD_SET_CREATE(
	subcmd_gcov,
	SHELL_CMD_ARG(dump, NULL,
			"Print gcov dump\n",
			gcov_dump, 0, 0),
	SHELL_SUBCMD_SET_END);

SHELL_CMD_ARG_REGISTER(gcov, &subcmd_gcov, "GCOV commands", NULL, 0, 0);
```

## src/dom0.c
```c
/*
 * Copyright (c) 2024 EPAM Systems
 *
 * SPDX-License-Identifier: Apache-2.0
 */

#include <domain.h>
#include <zephyr/kernel.h>
#include <zephyr/logging/log.h>

LOG_MODULE_REGISTER(dom0);

#include "dom0.h"

extern struct dom0_domain_cfg domain_cfgs[];

int domain_get_user_cfg_count(void)
{
	int i = 0;

	while (domain_cfgs[i].domain_cfg) {
		i++;
	}

	return i;
}

struct xen_domain_cfg *domain_get_user_cfg(int index)
{
	if (index < domain_get_user_cfg_count()) {
		return domain_cfgs[index].domain_cfg;
	}

	return NULL;
}

int main(void)
{
	int ret;
	int i = 0;

	ret = storage_init();
	if (ret) {
		goto exit_err;
	}

	/* It's required to init xenlib struct xen_domain_cfg->image_info with pointer
	 * at struct dom0_domain_cfg, so it can be passed in binary images loading callbacks like
	 * .load_image_bytes()/get_image_size(). It's the only way to pass app data
	 * back from xenlib.
	 */
	while (domain_cfgs[i].domain_cfg) {
		domain_cfgs[i].domain_cfg->image_info = &domain_cfgs[i];
		i++;
	}

exit_err:
	return ret;
}
```

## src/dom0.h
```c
/*
 * Copyright (c) 2024 EPAM Systems
 *
 * SPDX-License-Identifier: Apache-2.0
 */

#ifndef ZEPHYR_DOM0_XT_SRC_DOM0_H_
#define ZEPHYR_DOM0_XT_SRC_DOM0_H_

/**
 * @brief Dom0 domain's configuration data structure.
 *
 * Hold Dom0 application specific configuration data for Xen guest domains.
 */
struct dom0_domain_cfg {
	struct xen_domain_cfg *domain_cfg; /**< xenlib domain cfg */

	/**
	 * @brief Dom0 configuration init callback.
	 *
	 * Callback that allows to execute some init routine before starting
	 * domain. Such routine can be parsing pv parameters.
	 */
	void (*init)(void);
	const char *image_kernel_path; /**< disk: domain kernel binary path */
	const char *image_dt_path; /**< disk: domain partial device-tree (PDT) binary path */
};

#if defined(CONFIG_DOM_STORAGE_FATFS_ENABLE)
#define DISK_DRIVE_NAME CONFIG_DOM_DISK_DRIVE_NAME
#define DISK_MOUNT_PT "/"CONFIG_DOM_STORAGE_FATFS_LOGICAL_DRIVE_NAME":"
#define DISK_BIN_PATH DISK_MOUNT_PT"/"CONFIG_DOM_STORAGE_FATFS_DIR

int storage_init(void);
int storage_image_kernel_read(uint8_t *buf, size_t bufsize, uint64_t offset, void *image_info);
ssize_t storage_image_kernel_get_size(void *image_info, uint64_t *size);
int storage_image_dt_read(uint8_t *buf, size_t bufsize, uint64_t offset, void *image_info);
int storage_image_dt_get_size(void *image_info, size_t *size);
#else

static inline int storage_init(void)
{
	return 0;
}
#endif /* CONFIG_DOM_STORAGE_FATFS_ENABLE */

#endif /* ZEPHYR_DOM0_XT_SRC_DOM0_H_ */
```

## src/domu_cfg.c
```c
/*
 * Copyright (c) 2023 EPAM Systems
 *
 * SPDX-License-Identifier: Apache-2.0
 */

#include <domain.h>
#include <zephyr/xen/public/domctl.h>

#include <string.h>

#include "dom0.h"

extern char __img_domu0_start[];
extern char __img_domu0_end[];
extern char __dtb_domu0_start[];
extern char __dtb_domu0_end[];

static int load_domu_image_bytes(uint8_t *buf, size_t bufsize,
		   uint64_t offset, void *image_info)
{
	ARG_UNUSED(image_info);

	memcpy(buf, __img_domu0_start + offset, bufsize);
	return 0;
}

static ssize_t get_domu_image_size(void *image_info, uint64_t *size)
{
	ARG_UNUSED(image_info);

	*size = __img_domu0_end - __img_domu0_start;
	return 0;
}

static struct xen_domain_cfg domu_cfg_0 = {
	.name = "domu_default",
	.mem_kb = 16384,

	.flags = (XEN_DOMCTL_CDF_hvm | XEN_DOMCTL_CDF_hap),
	.max_evtchns = 10,
	.max_vcpus = 4,
	.gnt_frames = 32,
	.max_maptrack_frames = 1,

	.gic_version =
		IS_ENABLED(CONFIG_GIC_V3) ? XEN_DOMCTL_CONFIG_GIC_V3 : XEN_DOMCTL_CONFIG_GIC_V2,
	.tee_type = XEN_DOMCTL_CONFIG_TEE_NONE,

	.load_image_bytes = load_domu_image_bytes,
	.get_image_size = get_domu_image_size,

	.dtb_start = __dtb_domu0_start,
	.dtb_end = __dtb_domu0_end,
};

struct dom0_domain_cfg domain_cfgs[] = {
	{
		.domain_cfg = &domu_cfg_0,
	},
	{ 0 },
};
```

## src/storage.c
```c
/*
 * Copyright (c) 2024 EPAM Systems
 *
 * SPDX-License-Identifier: Apache-2.0
 */

#include <zephyr/kernel.h>
#include <zephyr/fs/fs.h>
#include <zephyr/logging/log.h>
#include <zephyr/storage/disk_access.h>

LOG_MODULE_REGISTER(dom0_storage);

#include <ff.h>
#include <storage.h>

#include "dom0.h"

static FATFS fat_fs;
/* mounting info */
static struct fs_mount_t mp = {
	.type = FS_FATFS,
	.fs_data = &fat_fs,
};

#if defined(CONFIG_FS_FATFS_MULTI_PARTITION)
PARTITION VolToPart[FF_VOLUMES] = {
    [0] = {3, 1},     /* "0:" ==> 1st partition on the pd#0 */
    [1] = {3, 2},     /* "1:" ==> 2nd partition on the pd#0 */
    [2] = {0, -1},     /* "2:" ==> 3rd partition on the pd#0 */
    [3] = {0, -1},
    [4] = {0, -1},
    [5] = {0, -1},
    [6] = {0, -1},
    [7] = {0, -1},
};
#endif /* CONFIG_FS_FATFS_MULTI_PARTITION */

int storage_image_kernel_read(uint8_t *buf, size_t bufsize, uint64_t offset, void *image_info)
{
	struct dom0_domain_cfg *dom_cfg = image_info;

	LOG_INF("storage: file read %s size: %zd", dom_cfg->image_kernel_path, bufsize);
	return xrun_read_file(dom_cfg->image_kernel_path, buf, bufsize, offset);
}

ssize_t storage_image_kernel_get_size(void *image_info, uint64_t *size)
{
	struct dom0_domain_cfg *dom_cfg = image_info;
	ssize_t r_size;

	r_size = xrun_get_file_size(dom_cfg->image_kernel_path);
	if (r_size >= 0) {
		*size = r_size;
		return 0;
	}

	return r_size;
}

int storage_image_dt_read(uint8_t *buf, size_t bufsize, uint64_t offset, void *image_info)
{
	struct dom0_domain_cfg *dom_cfg = image_info;

	LOG_INF("storage: file read %s size: %zd", dom_cfg->image_dt_path, bufsize);
	return xrun_read_file(dom_cfg->image_dt_path, buf, bufsize, offset);
}

int storage_image_dt_get_size(void *image_info, size_t *size)
{
	struct dom0_domain_cfg *dom_cfg = image_info;
	ssize_t r_size;

	r_size = xrun_get_file_size(dom_cfg->image_dt_path);
	if (r_size >= 0) {
		*size = r_size;
		return 0;
	}

	return r_size;
}

int storage_init(void)
{
	uint64_t memory_size_mb;
	struct fs_dir_t dirp;
	uint32_t block_count;
	uint32_t block_size;

	int ret;

	ret = disk_access_init(DISK_DRIVE_NAME);
	if (ret) {
		LOG_ERR("storage: init failed (%d)", ret);
		goto exit_err;
	}

	ret = disk_access_ioctl(DISK_DRIVE_NAME, DISK_IOCTL_GET_SECTOR_COUNT, &block_count);
	if (ret) {
		LOG_ERR("storage: get sector count failed (%d)", ret);
		goto exit_err;
	}

	ret = disk_access_ioctl(DISK_DRIVE_NAME, DISK_IOCTL_GET_SECTOR_SIZE, &block_size);
	if (ret) {
		LOG_ERR("storage: get sector size failed (%d)", ret);
		goto exit_err;
	}

	memory_size_mb = (uint64_t)block_count * block_size;
	LOG_INF("storage: block count %u, Sector size %u, Memory Size(MB) %u", block_count,
		block_size, (uint32_t)(memory_size_mb >> 20));

	mp.mnt_point = DISK_MOUNT_PT;

	ret = fs_mount(&mp);
	if (ret) {
		LOG_ERR("storage: mount failed (%d)", ret);
		goto exit_err;
	}
	LOG_INF("storage: mounted, binaries folder %s", DISK_BIN_PATH);

	/* Verify binaries folder */
	fs_dir_t_init(&dirp);
	ret = fs_opendir(&dirp, DISK_BIN_PATH);
	if (ret) {
		LOG_ERR("storage: error opening dir %s [%d]\n", DISK_BIN_PATH, ret);
		return ret;
	}

	fs_closedir(&dirp);

exit_err:
	return ret;
}
```

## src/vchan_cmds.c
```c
/*
 * Copyright (c) 2024 EPAM Systems
 *
 * SPDX-License-Identifier: Apache-2.0
 */

#include <domain.h>
#include <vch.h>
#include <zephyr/kernel.h>
#include <zephyr/logging/log.h>
#include <zephyr/shell/shell.h>

LOG_MODULE_REGISTER(vchan_cmd);

#define ECHO_SERVER_THREAD_PRIO    7
#define PATH_TEMPLATE "/local/domain/%d/echo"
#define THREAD_NAME "vchan_echo_server"

static struct k_thread echo_thread;
static struct k_thread *pecho_thread = NULL;
static struct vch_handle handle;

static K_THREAD_STACK_DEFINE(echo_thread_stack, CONFIG_VCHAN_THREAD_STACK_SIZE);
static volatile int vchan_server_stop = 0;

static void vchan_echo_server(void *p1, void *p2, void *p3)
{
	struct vch_handle *h = (struct vch_handle *)p1;
	int size;
	static char buf[CONFIG_VCHAN_ECHO_BUFFER_SIZE];

	ARG_UNUSED(p2);
	ARG_UNUSED(p3);
	LOG_DBG("Server started\n");
	while (!vchan_server_stop) {
		size = vch_read(h, buf, sizeof(buf));
		if (size > 0) {
			vch_write(h, buf, size);
		} else {
			if (size < 0 && size != -ENOTCONN) {
				LOG_ERR("vch_read returned %d\r", size);
			}
			k_sleep(K_MSEC(500));
		}
	}
	LOG_DBG("Server stopped\n");
	vch_close(h);
}

static int vchan_shell_start(const struct shell *sh, size_t argc, char **argv)
{
	int ret;
	domid_t domid = 0;
	static char path[PATH_MAX];

	if (pecho_thread) {
		shell_warn(sh, "Server already started");
		return 1;
	}
	if (argv[1]) {
		domid = atoi(argv[1]);
	}
	snprintf(path, PATH_MAX-1, PATH_TEMPLATE, domid);
	ret = vch_open(domid, path, 10, 10, &handle);
	if (ret) {
		shell_error(sh, "vchan open error %d", ret);
		goto exit;
	}
	shell_print(sh, "Echo server openad at %s", path);
	vchan_server_stop = 0;
	k_thread_create(&echo_thread, echo_thread_stack, K_THREAD_STACK_SIZEOF(echo_thread_stack),
			vchan_echo_server, (void *)&handle, NULL, NULL,
			ECHO_SERVER_THREAD_PRIO, 0, K_NO_WAIT);
	pecho_thread = &echo_thread;
	k_thread_name_set(pecho_thread, THREAD_NAME);

exit:
	return ret;
}

static int vchan_shell_stop(const struct shell *sh, size_t argc, char **argv)
{
	if (!pecho_thread) {
		shell_warn(sh, "Server not started");
		return 0;
	}
	vchan_server_stop = 1;
	if (k_thread_join(pecho_thread, K_MSEC(1000))) {
		shell_error(sh, "Killing thread");
		k_thread_abort(pecho_thread);
	}
	pecho_thread = NULL;
	return 0;
}

SHELL_STATIC_SUBCMD_SET_CREATE(
	subcmd_vchan,
	SHELL_CMD_ARG(start, NULL,
		      "start echo server.\n"
		      "\tUsage:\n"
		      "\tvchan start [domid]\n",
		      vchan_shell_start, 0, 1),
	SHELL_CMD_ARG(stop, NULL,
		      "stop server.\n",
		      vchan_shell_stop, 0, 0),
	SHELL_SUBCMD_SET_END);

SHELL_CMD_ARG_REGISTER(vchan, &subcmd_vchan, "VCHAN commands", NULL, 2, 0);
```
